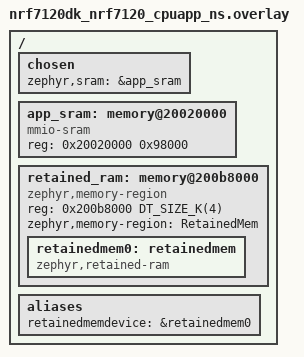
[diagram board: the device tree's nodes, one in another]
/*
 * Copyright (c) 2026 Nordic Semiconductor ASA
 *
 * SPDX-License-Identifier: LicenseRef-Nordic-5-Clause
 */

/ {
	chosen {
		zephyr,sram = &app_sram;
	};

	app_sram: memory@20020000 {
		compatible = "mmio-sram";
		reg = <0x20020000 0x98000>;
	};

	retained_ram: memory@200b8000 {
		compatible = "zephyr,memory-region", "mmio-sram";
		reg = <0x200b8000 DT_SIZE_K(4)>;
		zephyr,memory-region = "RetainedMem";
		status = "okay";

		retainedmem0: retainedmem {
			compatible = "zephyr,retained-ram";
			status = "okay";
		};
	};

	aliases {
		retainedmemdevice = &retainedmem0;
	};
};
